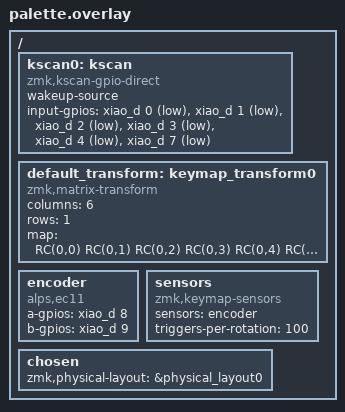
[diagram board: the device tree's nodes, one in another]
#include <dt-bindings/zmk/matrix_transform.h>
#include "palette-layouts.dtsi"

/ {
    kscan0: kscan {
        compatible = "zmk,kscan-gpio-direct";
        wakeup-source;
        input-gpios
            = <&xiao_d 0 (GPIO_ACTIVE_LOW | GPIO_PULL_UP)>
            , <&xiao_d 1 (GPIO_ACTIVE_LOW | GPIO_PULL_UP)>
            , <&xiao_d 2 (GPIO_ACTIVE_LOW | GPIO_PULL_UP)>
            , <&xiao_d 3 (GPIO_ACTIVE_LOW | GPIO_PULL_UP)>
            , <&xiao_d 4 (GPIO_ACTIVE_LOW | GPIO_PULL_UP)>
            , <&xiao_d 7 (GPIO_ACTIVE_LOW | GPIO_PULL_UP)>
            ;
    };
    default_transform: keymap_transform0 {
        compatible = "zmk,matrix-transform";
        columns = <6>;
        rows = <1>;
        map = <
          RC(0,0) RC(0,1) RC(0,2) RC(0,3) RC(0,4) RC(0,5)
        >;
    };
    encoder: encoder {
        compatible = "alps,ec11";
        a-gpios = <&xiao_d 8 (GPIO_ACTIVE_HIGH | GPIO_PULL_UP)>;
        b-gpios = <&xiao_d 9 (GPIO_ACTIVE_HIGH | GPIO_PULL_UP)>;
        status = "okay";
    };
    sensors: sensors {
        compatible = "zmk,keymap-sensors";
        sensors = <&encoder>;
        triggers-per-rotation = <100>;
    };

    chosen {
        zmk,physical-layout = &physical_layout0;
    };

};
